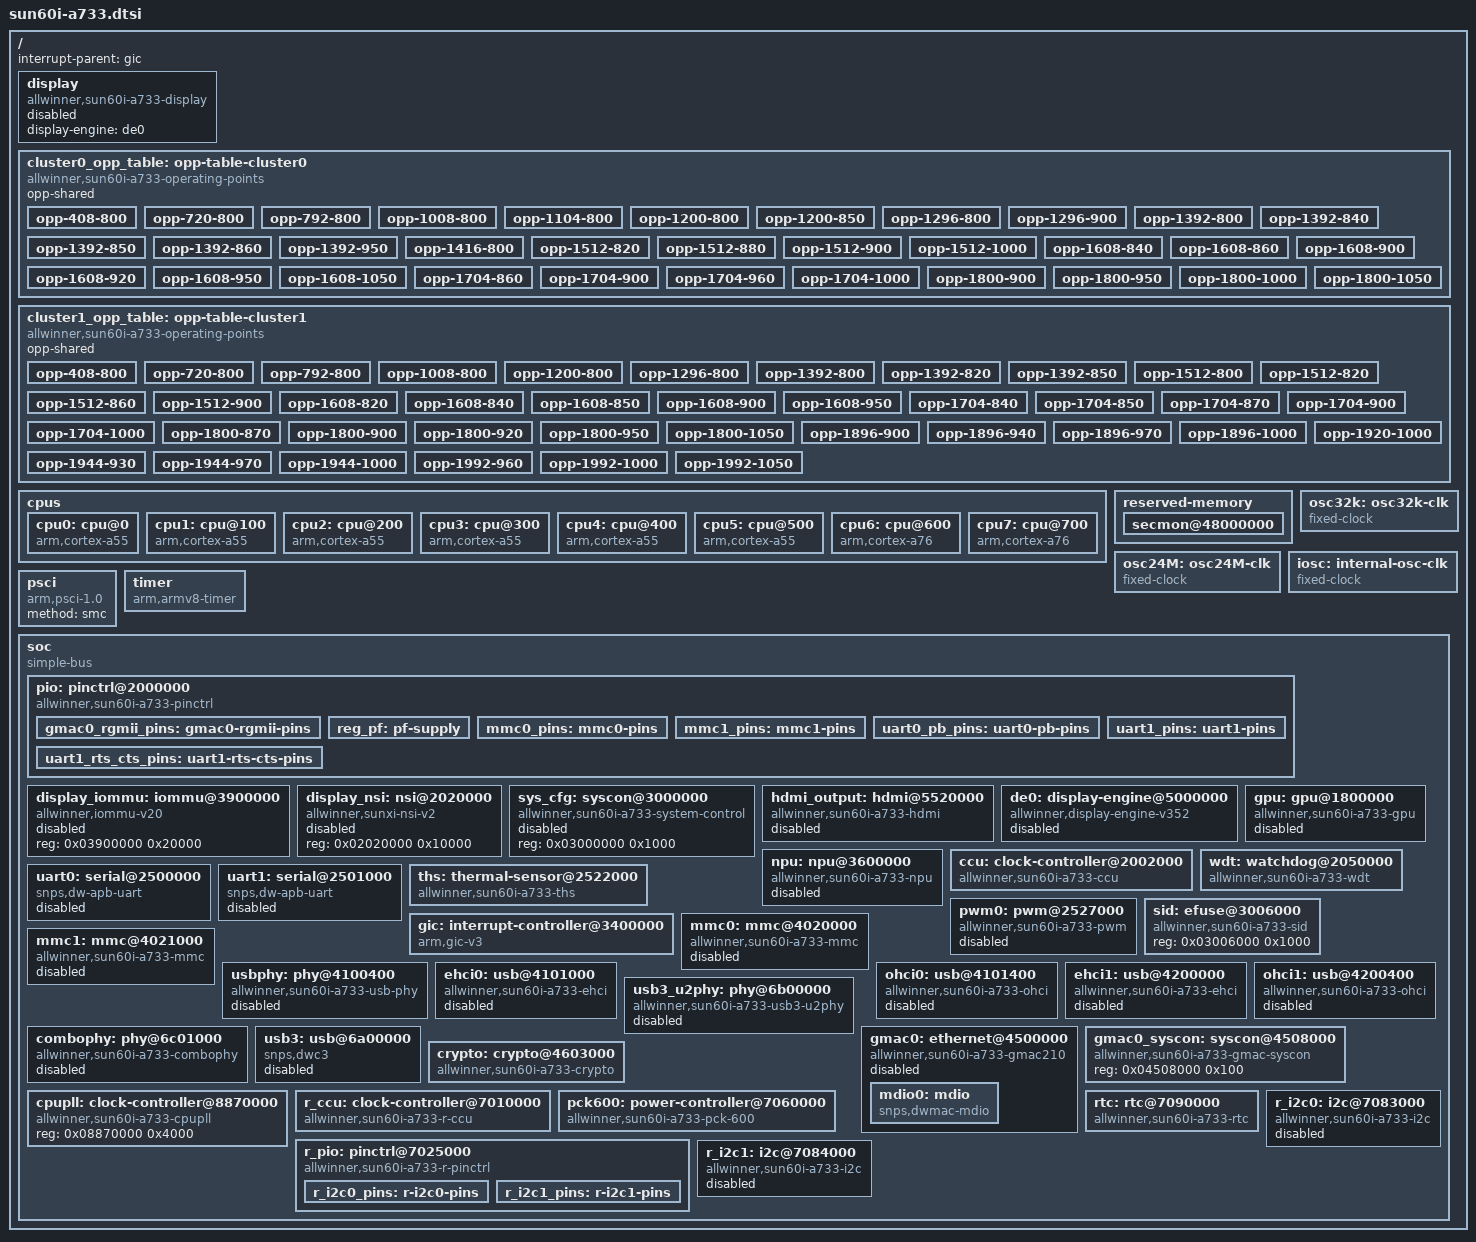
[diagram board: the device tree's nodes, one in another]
// SPDX-License-Identifier: (GPL-2.0-only OR MIT)
/*
 * Allwinner A733 (sun60iw2).
 *
 * Addresses and interrupt numbers were checked against the vendor kernel
 * tree and, where a register could be read, on an Orange Pi Zero 4.
 */

#include <dt-bindings/interrupt-controller/arm-gic.h>
#include <dt-bindings/clock/allwinner,sun60i-a733-ccu.h>
#include <dt-bindings/clock/allwinner,sun60i-a733-r-ccu.h>
#include <dt-bindings/reset/allwinner,sun60i-a733-ccu.h>
#include <dt-bindings/reset/allwinner,sun60i-a733-r-ccu.h>
#include <dt-bindings/power/allwinner,sun60i-a733-pck-600.h>

/ {
	/* This frontend does not enable DE, clocks or output at attach. */
	display: display {
		compatible = "allwinner,sun60i-a733-display";
		display-engine = <&de0>;
		status = "disabled";
	};

	interrupt-parent = <&gic>;
	#address-cells = <2>;
	#size-cells = <2>;

	/*
	 * Rates and supply voltages per speed grade. Bit n of
	 * "opp-supported-hw" stands for the n-th of the grades 0x00, 0x01,
	 * 0x02, 0x03, 0x04, 0x05, 0x06, 0x14 and 0x15 in the EFUSE. A board
	 * points its cores here together with their supplies: without a
	 * supply the higher rates must not be used.
	 */
	cluster0_opp_table: opp-table-cluster0 {
		compatible = "allwinner,sun60i-a733-operating-points";
		opp-shared;

		opp-408-800 {
			opp-hz = /bits/ 64 <408000000>;
			opp-microvolt = <800000>;
			opp-supported-hw = <0x1ff>;
			clock-latency-ns = <2000000>;
		};

		opp-720-800 {
			opp-hz = /bits/ 64 <720000000>;
			opp-microvolt = <800000>;
			opp-supported-hw = <0x001>;
			clock-latency-ns = <2000000>;
		};

		opp-792-800 {
			opp-hz = /bits/ 64 <792000000>;
			opp-microvolt = <800000>;
			opp-supported-hw = <0x1fe>;
			clock-latency-ns = <2000000>;
		};

		opp-1008-800 {
			opp-hz = /bits/ 64 <1008000000>;
			opp-microvolt = <800000>;
			opp-supported-hw = <0x1ff>;
			clock-latency-ns = <2000000>;
		};

		opp-1104-800 {
			opp-hz = /bits/ 64 <1104000000>;
			opp-microvolt = <800000>;
			opp-supported-hw = <0x002>;
			clock-latency-ns = <2000000>;
		};

		opp-1200-800 {
			opp-hz = /bits/ 64 <1200000000>;
			opp-microvolt = <800000>;
			opp-supported-hw = <0x1fd>;
			clock-latency-ns = <2000000>;
		};

		opp-1200-850 {
			opp-hz = /bits/ 64 <1200000000>;
			opp-microvolt = <850000>;
			opp-supported-hw = <0x002>;
			clock-latency-ns = <2000000>;
		};

		opp-1296-800 {
			opp-hz = /bits/ 64 <1296000000>;
			opp-microvolt = <800000>;
			opp-supported-hw = <0x004>;
			clock-latency-ns = <2000000>;
		};

		opp-1296-900 {
			opp-hz = /bits/ 64 <1296000000>;
			opp-microvolt = <900000>;
			opp-supported-hw = <0x002>;
			clock-latency-ns = <2000000>;
		};

		opp-1392-800 {
			opp-hz = /bits/ 64 <1392000000>;
			opp-microvolt = <800000>;
			opp-supported-hw = <0x1a0>;
			clock-latency-ns = <2000000>;
		};

		opp-1392-840 {
			opp-hz = /bits/ 64 <1392000000>;
			opp-microvolt = <840000>;
			opp-supported-hw = <0x050>;
			clock-latency-ns = <2000000>;
		};

		opp-1392-850 {
			opp-hz = /bits/ 64 <1392000000>;
			opp-microvolt = <850000>;
			opp-supported-hw = <0x004>;
			clock-latency-ns = <2000000>;
		};

		opp-1392-860 {
			opp-hz = /bits/ 64 <1392000000>;
			opp-microvolt = <860000>;
			opp-supported-hw = <0x008>;
			clock-latency-ns = <2000000>;
		};

		opp-1392-950 {
			opp-hz = /bits/ 64 <1392000000>;
			opp-microvolt = <950000>;
			opp-supported-hw = <0x002>;
			clock-latency-ns = <2000000>;
		};

		opp-1416-800 {
			opp-hz = /bits/ 64 <1416000000>;
			opp-microvolt = <800000>;
			opp-supported-hw = <0x001>;
			clock-latency-ns = <2000000>;
		};

		opp-1512-820 {
			opp-hz = /bits/ 64 <1512000000>;
			opp-microvolt = <820000>;
			opp-supported-hw = <0x1a0>;
			clock-latency-ns = <2000000>;
		};

		opp-1512-880 {
			opp-hz = /bits/ 64 <1512000000>;
			opp-microvolt = <880000>;
			opp-supported-hw = <0x010>;
			clock-latency-ns = <2000000>;
		};

		opp-1512-900 {
			opp-hz = /bits/ 64 <1512000000>;
			opp-microvolt = <900000>;
			opp-supported-hw = <0x004>;
			clock-latency-ns = <2000000>;
		};

		opp-1512-1000 {
			opp-hz = /bits/ 64 <1512000000>;
			opp-microvolt = <1000000>;
			opp-supported-hw = <0x002>;
			clock-latency-ns = <2000000>;
		};

		opp-1608-840 {
			opp-hz = /bits/ 64 <1608000000>;
			opp-microvolt = <840000>;
			opp-supported-hw = <0x100>;
			clock-latency-ns = <2000000>;
		};

		opp-1608-860 {
			opp-hz = /bits/ 64 <1608000000>;
			opp-microvolt = <860000>;
			opp-supported-hw = <0x0a0>;
			clock-latency-ns = <2000000>;
		};

		opp-1608-900 {
			opp-hz = /bits/ 64 <1608000000>;
			opp-microvolt = <900000>;
			opp-supported-hw = <0x001>;
			clock-latency-ns = <2000000>;
		};

		opp-1608-920 {
			opp-hz = /bits/ 64 <1608000000>;
			opp-microvolt = <920000>;
			opp-supported-hw = <0x010>;
			clock-latency-ns = <2000000>;
		};

		opp-1608-950 {
			opp-hz = /bits/ 64 <1608000000>;
			opp-microvolt = <950000>;
			opp-supported-hw = <0x004>;
			clock-latency-ns = <2000000>;
		};

		opp-1608-1050 {
			opp-hz = /bits/ 64 <1608000000>;
			opp-microvolt = <1050000>;
			opp-supported-hw = <0x002>;
			clock-latency-ns = <2000000>;
		};

		opp-1704-860 {
			opp-hz = /bits/ 64 <1704000000>;
			opp-microvolt = <860000>;
			opp-supported-hw = <0x100>;
			clock-latency-ns = <2000000>;
		};

		opp-1704-900 {
			opp-hz = /bits/ 64 <1704000000>;
			opp-microvolt = <900000>;
			opp-supported-hw = <0x0a0>;
			clock-latency-ns = <2000000>;
		};

		opp-1704-960 {
			opp-hz = /bits/ 64 <1704000000>;
			opp-microvolt = <960000>;
			opp-supported-hw = <0x010>;
			clock-latency-ns = <2000000>;
		};

		opp-1704-1000 {
			opp-hz = /bits/ 64 <1704000000>;
			opp-microvolt = <1000000>;
			opp-supported-hw = <0x004>;
			clock-latency-ns = <2000000>;
		};

		opp-1800-900 {
			opp-hz = /bits/ 64 <1800000000>;
			opp-microvolt = <900000>;
			opp-supported-hw = <0x100>;
			clock-latency-ns = <2000000>;
		};

		opp-1800-950 {
			opp-hz = /bits/ 64 <1800000000>;
			opp-microvolt = <950000>;
			opp-supported-hw = <0x0a0>;
			clock-latency-ns = <2000000>;
		};

		opp-1800-1000 {
			opp-hz = /bits/ 64 <1800000000>;
			opp-microvolt = <1000000>;
			opp-supported-hw = <0x011>;
			clock-latency-ns = <2000000>;
		};

		opp-1800-1050 {
			opp-hz = /bits/ 64 <1800000000>;
			opp-microvolt = <1050000>;
			opp-supported-hw = <0x004>;
			clock-latency-ns = <2000000>;
		};
	};

	cluster1_opp_table: opp-table-cluster1 {
		compatible = "allwinner,sun60i-a733-operating-points";
		opp-shared;

		opp-408-800 {
			opp-hz = /bits/ 64 <408000000>;
			opp-microvolt = <800000>;
			opp-supported-hw = <0x1ff>;
			clock-latency-ns = <2000000>;
		};

		opp-720-800 {
			opp-hz = /bits/ 64 <720000000>;
			opp-microvolt = <800000>;
			opp-supported-hw = <0x001>;
			clock-latency-ns = <2000000>;
		};

		opp-792-800 {
			opp-hz = /bits/ 64 <792000000>;
			opp-microvolt = <800000>;
			opp-supported-hw = <0x1fe>;
			clock-latency-ns = <2000000>;
		};

		opp-1008-800 {
			opp-hz = /bits/ 64 <1008000000>;
			opp-microvolt = <800000>;
			opp-supported-hw = <0x1ff>;
			clock-latency-ns = <2000000>;
		};

		opp-1200-800 {
			opp-hz = /bits/ 64 <1200000000>;
			opp-microvolt = <800000>;
			opp-supported-hw = <0x1ff>;
			clock-latency-ns = <2000000>;
		};

		opp-1296-800 {
			opp-hz = /bits/ 64 <1296000000>;
			opp-microvolt = <800000>;
			opp-supported-hw = <0x002>;
			clock-latency-ns = <2000000>;
		};

		opp-1392-800 {
			opp-hz = /bits/ 64 <1392000000>;
			opp-microvolt = <800000>;
			opp-supported-hw = <0x1f5>;
			clock-latency-ns = <2000000>;
		};

		opp-1392-820 {
			opp-hz = /bits/ 64 <1392000000>;
			opp-microvolt = <820000>;
			opp-supported-hw = <0x008>;
			clock-latency-ns = <2000000>;
		};

		opp-1392-850 {
			opp-hz = /bits/ 64 <1392000000>;
			opp-microvolt = <850000>;
			opp-supported-hw = <0x002>;
			clock-latency-ns = <2000000>;
		};

		opp-1512-800 {
			opp-hz = /bits/ 64 <1512000000>;
			opp-microvolt = <800000>;
			opp-supported-hw = <0x1e5>;
			clock-latency-ns = <2000000>;
		};

		opp-1512-820 {
			opp-hz = /bits/ 64 <1512000000>;
			opp-microvolt = <820000>;
			opp-supported-hw = <0x010>;
			clock-latency-ns = <2000000>;
		};

		opp-1512-860 {
			opp-hz = /bits/ 64 <1512000000>;
			opp-microvolt = <860000>;
			opp-supported-hw = <0x008>;
			clock-latency-ns = <2000000>;
		};

		opp-1512-900 {
			opp-hz = /bits/ 64 <1512000000>;
			opp-microvolt = <900000>;
			opp-supported-hw = <0x002>;
			clock-latency-ns = <2000000>;
		};

		opp-1608-820 {
			opp-hz = /bits/ 64 <1608000000>;
			opp-microvolt = <820000>;
			opp-supported-hw = <0x1a0>;
			clock-latency-ns = <2000000>;
		};

		opp-1608-840 {
			opp-hz = /bits/ 64 <1608000000>;
			opp-microvolt = <840000>;
			opp-supported-hw = <0x010>;
			clock-latency-ns = <2000000>;
		};

		opp-1608-850 {
			opp-hz = /bits/ 64 <1608000000>;
			opp-microvolt = <850000>;
			opp-supported-hw = <0x045>;
			clock-latency-ns = <2000000>;
		};

		opp-1608-900 {
			opp-hz = /bits/ 64 <1608000000>;
			opp-microvolt = <900000>;
			opp-supported-hw = <0x008>;
			clock-latency-ns = <2000000>;
		};

		opp-1608-950 {
			opp-hz = /bits/ 64 <1608000000>;
			opp-microvolt = <950000>;
			opp-supported-hw = <0x002>;
			clock-latency-ns = <2000000>;
		};

		opp-1704-840 {
			opp-hz = /bits/ 64 <1704000000>;
			opp-microvolt = <840000>;
			opp-supported-hw = <0x100>;
			clock-latency-ns = <2000000>;
		};

		opp-1704-850 {
			opp-hz = /bits/ 64 <1704000000>;
			opp-microvolt = <850000>;
			opp-supported-hw = <0x0a0>;
			clock-latency-ns = <2000000>;
		};

		opp-1704-870 {
			opp-hz = /bits/ 64 <1704000000>;
			opp-microvolt = <870000>;
			opp-supported-hw = <0x010>;
			clock-latency-ns = <2000000>;
		};

		opp-1704-900 {
			opp-hz = /bits/ 64 <1704000000>;
			opp-microvolt = <900000>;
			opp-supported-hw = <0x005>;
			clock-latency-ns = <2000000>;
		};

		opp-1704-1000 {
			opp-hz = /bits/ 64 <1704000000>;
			opp-microvolt = <1000000>;
			opp-supported-hw = <0x002>;
			clock-latency-ns = <2000000>;
		};

		opp-1800-870 {
			opp-hz = /bits/ 64 <1800000000>;
			opp-microvolt = <870000>;
			opp-supported-hw = <0x100>;
			clock-latency-ns = <2000000>;
		};

		opp-1800-900 {
			opp-hz = /bits/ 64 <1800000000>;
			opp-microvolt = <900000>;
			opp-supported-hw = <0x0a0>;
			clock-latency-ns = <2000000>;
		};

		opp-1800-920 {
			opp-hz = /bits/ 64 <1800000000>;
			opp-microvolt = <920000>;
			opp-supported-hw = <0x010>;
			clock-latency-ns = <2000000>;
		};

		opp-1800-950 {
			opp-hz = /bits/ 64 <1800000000>;
			opp-microvolt = <950000>;
			opp-supported-hw = <0x005>;
			clock-latency-ns = <2000000>;
		};

		opp-1800-1050 {
			opp-hz = /bits/ 64 <1800000000>;
			opp-microvolt = <1050000>;
			opp-supported-hw = <0x002>;
			clock-latency-ns = <2000000>;
		};

		opp-1896-900 {
			opp-hz = /bits/ 64 <1896000000>;
			opp-microvolt = <900000>;
			opp-supported-hw = <0x100>;
			clock-latency-ns = <2000000>;
		};

		opp-1896-940 {
			opp-hz = /bits/ 64 <1896000000>;
			opp-microvolt = <940000>;
			opp-supported-hw = <0x0a0>;
			clock-latency-ns = <2000000>;
		};

		opp-1896-970 {
			opp-hz = /bits/ 64 <1896000000>;
			opp-microvolt = <970000>;
			opp-supported-hw = <0x010>;
			clock-latency-ns = <2000000>;
		};

		opp-1896-1000 {
			opp-hz = /bits/ 64 <1896000000>;
			opp-microvolt = <1000000>;
			opp-supported-hw = <0x004>;
			clock-latency-ns = <2000000>;
		};

		opp-1920-1000 {
			opp-hz = /bits/ 64 <1920000000>;
			opp-microvolt = <1000000>;
			opp-supported-hw = <0x001>;
			clock-latency-ns = <2000000>;
		};

		opp-1944-930 {
			opp-hz = /bits/ 64 <1944000000>;
			opp-microvolt = <930000>;
			opp-supported-hw = <0x100>;
			clock-latency-ns = <2000000>;
		};

		opp-1944-970 {
			opp-hz = /bits/ 64 <1944000000>;
			opp-microvolt = <970000>;
			opp-supported-hw = <0x0a0>;
			clock-latency-ns = <2000000>;
		};

		opp-1944-1000 {
			opp-hz = /bits/ 64 <1944000000>;
			opp-microvolt = <1000000>;
			opp-supported-hw = <0x010>;
			clock-latency-ns = <2000000>;
		};

		opp-1992-960 {
			opp-hz = /bits/ 64 <1992000000>;
			opp-microvolt = <960000>;
			opp-supported-hw = <0x100>;
			clock-latency-ns = <2000000>;
		};

		opp-1992-1000 {
			opp-hz = /bits/ 64 <1992000000>;
			opp-microvolt = <1000000>;
			opp-supported-hw = <0x0a0>;
			clock-latency-ns = <2000000>;
		};

		opp-1992-1050 {
			opp-hz = /bits/ 64 <1992000000>;
			opp-microvolt = <1050000>;
			opp-supported-hw = <0x011>;
			clock-latency-ns = <2000000>;
		};
	};

	cpus {
		#address-cells = <1>;
		#size-cells = <0>;

		cpu0: cpu@0 {
			compatible = "arm,cortex-a55";
			device_type = "cpu";
			reg = <0x000>;
			enable-method = "psci";
			clocks = <&cpupll 0>;
		};

		cpu1: cpu@100 {
			compatible = "arm,cortex-a55";
			device_type = "cpu";
			reg = <0x100>;
			enable-method = "psci";
			clocks = <&cpupll 0>;
		};

		cpu2: cpu@200 {
			compatible = "arm,cortex-a55";
			device_type = "cpu";
			reg = <0x200>;
			enable-method = "psci";
			clocks = <&cpupll 0>;
		};

		cpu3: cpu@300 {
			compatible = "arm,cortex-a55";
			device_type = "cpu";
			reg = <0x300>;
			enable-method = "psci";
			clocks = <&cpupll 0>;
		};

		cpu4: cpu@400 {
			compatible = "arm,cortex-a55";
			device_type = "cpu";
			reg = <0x400>;
			enable-method = "psci";
			clocks = <&cpupll 0>;
		};

		cpu5: cpu@500 {
			compatible = "arm,cortex-a55";
			device_type = "cpu";
			reg = <0x500>;
			enable-method = "psci";
			clocks = <&cpupll 0>;
		};

		cpu6: cpu@600 {
			compatible = "arm,cortex-a76";
			device_type = "cpu";
			reg = <0x600>;
			enable-method = "psci";
			clocks = <&cpupll 1>;
		};

		cpu7: cpu@700 {
			compatible = "arm,cortex-a76";
			device_type = "cpu";
			reg = <0x700>;
			enable-method = "psci";
			clocks = <&cpupll 1>;
		};
	};

	reserved-memory {
		#address-cells = <2>;
		#size-cells = <2>;
		ranges;

		/* EL3 monitor (BL31) */
		secmon@48000000 {
			reg = <0x0 0x48000000 0x0 0x01000000>;
			no-map;
		};
	};

	osc24M: osc24M-clk {
		#clock-cells = <0>;
		compatible = "fixed-clock";
		clock-frequency = <24000000>;
		clock-output-names = "osc24M";
	};

	osc32k: osc32k-clk {
		#clock-cells = <0>;
		compatible = "fixed-clock";
		clock-frequency = <32768>;
		clock-output-names = "osc32k";
	};

	iosc: internal-osc-clk {
		#clock-cells = <0>;
		compatible = "fixed-clock";
		clock-frequency = <16000000>;
		clock-output-names = "iosc";
	};

	psci {
		compatible = "arm,psci-1.0";
		method = "smc";
	};

	timer {
		compatible = "arm,armv8-timer";
		interrupts = <GIC_PPI 13 IRQ_TYPE_LEVEL_LOW>,
			     <GIC_PPI 14 IRQ_TYPE_LEVEL_LOW>,
			     <GIC_PPI 11 IRQ_TYPE_LEVEL_LOW>,
			     <GIC_PPI 10 IRQ_TYPE_LEVEL_LOW>;
	};

	soc {
		compatible = "simple-bus";
		#address-cells = <1>;
		#size-cells = <1>;
		ranges = <0x0 0x0 0x0 0x40000000>;

		pio: pinctrl@2000000 {
			compatible = "allwinner,sun60i-a733-pinctrl";
			reg = <0x02000000 0x800>;
			clocks = <&ccu CLK_APB1>, <&osc24M>, <&osc32k>;
			clock-names = "apb", "hosc", "losc";
			gpio-controller;
			#gpio-cells = <3>;

			gmac0_rgmii_pins: gmac0-rgmii-pins {
				pins = "PH0", "PH1", "PH2", "PH3",
				       "PH4", "PH5", "PH6", "PH7",
				       "PH8", "PH9", "PH10", "PH11",
				       "PH12", "PH13", "PH14", "PH15";
				function = "gmac0";
				allwinner,pinmux = <5>;
				drive-strength = <20>;
				bias-pull-up;
			};

			/* The chip switches the supply of bank PF itself. */
			reg_pf: pf-supply {
				regulator-name = "vcc-pf";
				regulator-min-microvolt = <1800000>;
				regulator-max-microvolt = <3300000>;
			};

			mmc0_pins: mmc0-pins {
				pins = "PF0", "PF1", "PF2", "PF3", "PF4", "PF5";
				function = "mmc0";
				allwinner,pinmux = <2>;
				drive-strength = <30>;
				bias-pull-up;
			};

			mmc1_pins: mmc1-pins {
				pins = "PG0", "PG1", "PG2", "PG3", "PG4", "PG5";
				function = "mmc1";
				allwinner,pinmux = <2>;
				drive-strength = <20>;
				bias-pull-up;
			};

			uart0_pb_pins: uart0-pb-pins {
				pins = "PB9", "PB10";
				function = "uart0";
				allwinner,pinmux = <2>;
			};

			uart1_pins: uart1-pins {
				pins = "PG6", "PG7";
				function = "uart1";
				allwinner,pinmux = <2>;
			};

			uart1_rts_cts_pins: uart1-rts-cts-pins {
				pins = "PG8", "PG9";
				function = "uart1";
				allwinner,pinmux = <2>;
			};
		};

		/* Origin: EmberBSD, AI-assisted; native DE memory resource facts.
		 * These nodes do not register active IOMMU or NSI providers. */
		display_iommu: iommu@3900000 {
			compatible = "allwinner,iommu-v20";
			reg = <0x03900000 0x20000>;
			#iommu-cells = <2>;
			status = "disabled";
		};

		display_nsi: nsi@2020000 {
			compatible = "allwinner,sunxi-nsi-v2";
			reg = <0x02020000 0x10000>;
			#nsi-cells = <1>;
			status = "disabled";
		};

		/* Shared SYS_CFG access uses the native syscon mutex. */
		sys_cfg: syscon@3000000 {
			compatible = "allwinner,sun60i-a733-system-control", "syscon";
			reg = <0x03000000 0x1000>;
			status = "disabled";
		};

		/* Register the native provider. The DE coordinator starts output. */
		hdmi_output: hdmi@5520000 {
			compatible = "allwinner,sun60i-a733-hdmi";
			reg = <0x05520000 0x100000>, <0x05510000 0x1000>,
			      <0x05730000 0x1000>;
			reg-names = "hdmi", "vo1", "tv0";
			clocks = <&ccu CLK_DE0>;
			clock-names = "de0";
			power-domains = <&pck600 PD_VO1>;
			netbsd,consumer-managed-power;
			netbsd,dcxo-source = <&rtc>;
			syscon = <&sys_cfg>;
			status = "disabled";
		};

		/* An enabled board must supply its native output provider. */
		de0: display-engine@5000000 {
			compatible = "allwinner,display-engine-v352";
			reg = <0x05000000 0x400000>;
			clocks = <&ccu CLK_DE0>;
			clock-names = "de0";
			power-domains = <&pck600 PD_DE_SYS>;
			iommus = <&display_iommu 8 1>;
			nsi = <&display_nsi 2>;
			netbsd,consumer-managed-power;
			status = "disabled";
		};

		/* Origin: EmberBSD; GPU identity only, no automatic power-on. */
		gpu: gpu@1800000 {
			compatible = "allwinner,sun60i-a733-gpu",
				     "img,img-bxm-4-64", "img,img-rogue";
			reg = <0x01800000 0x8ffff>;
			interrupts = <GIC_SPI 63 IRQ_TYPE_LEVEL_HIGH>;
			clocks = <&ccu CLK_GPU0>;
			clock-names = "core";
			resets = <&ccu RST_BUS_GPU0>;
			power-domains = <&pck600 PD_GPU_TOP>;
			netbsd,consumer-managed-power;
			/* Local diagnostic stage: never map or read GPU registers. */
			netbsd,observe-only;
			status = "disabled";
		};

		/* Origin: EmberBSD; NPU identity only, no automatic power-on. */
		npu: npu@3600000 {
			compatible = "allwinner,sun60i-a733-npu";
			reg = <0x03600000 0x1000>;
			interrupts = <GIC_SPI 65 IRQ_TYPE_LEVEL_HIGH>;
			clocks = <&ccu CLK_NPU>, <&ccu CLK_PLL_NPU>,
				 <&ccu CLK_BUS_NPU>, <&ccu CLK_MBUS_NPU>,
				 <&ccu CLK_AHB_NPU>;
			clock-names = "clk_npu", "clk_parent", "clk_bus",
				"clk_mbus_gate", "clk_ahb_gate";
			resets = <&ccu RST_BUS_NPU_AHB>,
				 <&ccu RST_BUS_NPU_AXI>,
				 <&ccu RST_BUS_NPU_CORE>;
			reset-names = "npu_ahb_rst", "npu_axi_rst", "npu_rst";
			power-domains = <&pck600 4>;
			netbsd,consumer-managed-power;
			netbsd,observe-only;
			status = "disabled";
		};

		ccu: clock-controller@2002000 {
			compatible = "allwinner,sun60i-a733-ccu";
			/* Local read-only hardware oscillator observation source. */
			netbsd,dcxo-source = <&rtc>;
			reg = <0x02002000 0x2000>;
			clocks = <&osc24M>, <&osc32k>, <&iosc>, <&osc32k>;
			clock-names = "hosc", "losc", "iosc", "losc-fanout";
			#clock-cells = <1>;
			#reset-cells = <1>;
		};

		/* The same register layout as on the A523. */
		wdt: watchdog@2050000 {
			compatible = "allwinner,sun60i-a733-wdt",
				     "allwinner,sun55i-a523-wdt";
			reg = <0x02050000 0x20>;
			interrupts = <GIC_SPI 106 IRQ_TYPE_LEVEL_HIGH>;
			clocks = <&osc24M>, <&osc32k>;
			clock-names = "hosc", "losc";
		};

		uart0: serial@2500000 {
			compatible = "snps,dw-apb-uart";
			reg = <0x02500000 0x400>;
			interrupts = <GIC_SPI 2 IRQ_TYPE_LEVEL_HIGH>;
			reg-shift = <2>;
			reg-io-width = <4>;
			fifo-size = <64>;
			clocks = <&ccu CLK_BUS_UART0>;
			resets = <&ccu RST_BUS_UART0>;
			status = "disabled";
		};

		uart1: serial@2501000 {
			compatible = "snps,dw-apb-uart";
			reg = <0x02501000 0x400>;
			interrupts = <GIC_SPI 3 IRQ_TYPE_LEVEL_HIGH>;
			reg-shift = <2>;
			reg-io-width = <4>;
			fifo-size = <256>;
			clocks = <&ccu CLK_BUS_UART1>;
			resets = <&ccu RST_BUS_UART1>;
			status = "disabled";
		};

		/* Not an upstream binding yet. */
		ths: thermal-sensor@2522000 {
			compatible = "allwinner,sun60i-a733-ths";
			reg = <0x02522000 0x400>;
			clocks = <&ccu CLK_BUS_THS0>, <&ccu CLK_GPADC0_24M>;
			clock-names = "bus", "gpadc";
			resets = <&ccu RST_BUS_THS0>;
			#thermal-sensor-cells = <1>;
		};

		/* Native continuous PWM binding; capture is not implemented. */
		pwm0: pwm@2527000 {
			compatible = "allwinner,sun60i-a733-pwm";
			reg = <0x02527000 0x400>;
			clocks = <&ccu CLK_BUS_PWM0>, <&ccu CLK_BUS_PWM0>;
			clock-names = "bus", "hosc";
			resets = <&ccu RST_BUS_PWM0>;
			#pwm-cells = <3>;
			status = "disabled";
		};

		/* Not an upstream binding yet. */
		sid: efuse@3006000 {
			compatible = "allwinner,sun60i-a733-sid";
			reg = <0x03006000 0x1000>;
		};

		gic: interrupt-controller@3400000 {
			compatible = "arm,gic-v3";
			reg = <0x03400000 0x10000>,
			      <0x03460000 0x100000>;
			interrupts = <GIC_PPI 9 IRQ_TYPE_LEVEL_HIGH>;
			interrupt-controller;
			#interrupt-cells = <3>;
		};

		mmc0: mmc@4020000 {
			compatible = "allwinner,sun60i-a733-mmc",
				     "allwinner,sun20i-d1-mmc";
			reg = <0x04020000 0x1000>;
			interrupts = <GIC_SPI 161 IRQ_TYPE_LEVEL_HIGH>;
			clocks = <&ccu CLK_BUS_MMC0>, <&ccu CLK_MMC0>;
			clock-names = "ahb", "mmc";
			resets = <&ccu RST_BUS_MMC0>;
			reset-names = "ahb";
			max-frequency = <150000000>;
			cap-sd-highspeed;
			#address-cells = <1>;
			#size-cells = <0>;
			status = "disabled";
		};

		mmc1: mmc@4021000 {
			compatible = "allwinner,sun60i-a733-mmc",
				     "allwinner,sun20i-d1-mmc";
			reg = <0x04021000 0x1000>;
			interrupts = <GIC_SPI 162 IRQ_TYPE_LEVEL_HIGH>;
			clocks = <&ccu CLK_BUS_MMC1>, <&ccu CLK_MMC1>;
			clock-names = "ahb", "mmc";
			resets = <&ccu RST_BUS_MMC1>;
			reset-names = "ahb";
			max-frequency = <150000000>;
			cap-sd-highspeed;
			cap-sdio-irq;
			#address-cells = <1>;
			#size-cells = <0>;
			status = "disabled";
		};

		usbphy: phy@4100400 {
			compatible = "allwinner,sun60i-a733-usb-phy";
			reg = <0x04100400 0x100>,
			      <0x04101800 0x100>,
			      <0x04200800 0x100>;
			reg-names = "phy_ctrl", "pmu0", "pmu1";
			clocks = <&ccu CLK_USB_OHCI0>, <&ccu CLK_USB_OHCI1>;
			clock-names = "usb0_phy", "usb1_phy";
			resets = <&ccu RST_USB_PHY0>, <&ccu RST_USB_PHY1>;
			reset-names = "usb0_reset", "usb1_reset";
			#phy-cells = <1>;
			status = "disabled";
		};

		ehci0: usb@4101000 {
			compatible = "allwinner,sun60i-a733-ehci", "generic-ehci";
			reg = <0x04101000 0x100>;
			interrupts = <GIC_SPI 157 IRQ_TYPE_LEVEL_HIGH>;
			clocks = <&ccu CLK_BUS_OHCI0>, <&ccu CLK_BUS_EHCI0>,
				 <&ccu CLK_USB_OHCI0>;
			resets = <&ccu RST_BUS_OHCI0>, <&ccu RST_BUS_EHCI0>;
			phys = <&usbphy 0>;
			phy-names = "usb";
			status = "disabled";
		};

		ohci0: usb@4101400 {
			compatible = "allwinner,sun60i-a733-ohci", "generic-ohci";
			reg = <0x04101400 0x100>;
			interrupts = <GIC_SPI 158 IRQ_TYPE_LEVEL_HIGH>;
			clocks = <&ccu CLK_BUS_OHCI0>, <&ccu CLK_USB_OHCI0>;
			resets = <&ccu RST_BUS_OHCI0>;
			phys = <&usbphy 0>;
			phy-names = "usb";
			status = "disabled";
		};

		ehci1: usb@4200000 {
			compatible = "allwinner,sun60i-a733-ehci", "generic-ehci";
			reg = <0x04200000 0x100>;
			interrupts = <GIC_SPI 159 IRQ_TYPE_LEVEL_HIGH>;
			clocks = <&ccu CLK_BUS_OHCI1>, <&ccu CLK_BUS_EHCI1>,
				 <&ccu CLK_USB_OHCI1>;
			resets = <&ccu RST_BUS_OHCI1>, <&ccu RST_BUS_EHCI1>;
			phys = <&usbphy 1>;
			phy-names = "usb";
			status = "disabled";
		};

		ohci1: usb@4200400 {
			compatible = "allwinner,sun60i-a733-ohci", "generic-ohci";
			reg = <0x04200400 0x100>;
			interrupts = <GIC_SPI 160 IRQ_TYPE_LEVEL_HIGH>;
			clocks = <&ccu CLK_BUS_OHCI1>, <&ccu CLK_USB_OHCI1>;
			resets = <&ccu RST_BUS_OHCI1>;
			phys = <&usbphy 1>;
			phy-names = "usb";
			status = "disabled";
		};

		/*
		 * The USB 3 port. Its controller and PHYs belong to the
		 * high speed subsystem at 0x06c00000, whose bus gates the
		 * USB 2.0 PHY driver opens; that is the PHY's second
		 * register range. The compatible string of the PHY is not
		 * an upstream binding. The serdes for SuperSpeed is not
		 * described, so the port runs at USB 2.0 rates.
		 */
		usb3_u2phy: phy@6b00000 {
			compatible = "allwinner,sun60i-a733-usb3-u2phy";
			reg = <0x06b00000 0x800>, <0x06c00000 0x400>;
			clocks = <&ccu CLK_USB2_U2_REF>,
				 <&ccu CLK_USB2_U2_PIPE>;
			assigned-clocks = <&ccu CLK_USB2_U2_PIPE>;
			assigned-clock-parents = <&ccu CLK_PLL_PERIPH0_480M>;
			assigned-clock-rates = <120000000>;
			allwinner,phy-tune = <0x143338d6>;
			#phy-cells = <0>;
			status = "disabled";
		};

		/*
		 * The serdes behind the SuperSpeed lanes of the Type-C
		 * port. Registers: the PHY's pins, the PHY itself, the
		 * lane routing, the subsystem's gates, and the gate of
		 * the oscillator's outputs in the real-time clock. The
		 * compatible string is not an upstream binding.
		 */
		combophy: phy@6c01000 {
			compatible = "allwinner,sun60i-a733-combophy";
			reg = <0x06c01000 0xa00>, <0x06c80000 0x20000>,
			      <0x06c06000 0x2000>, <0x06c00000 0x400>,
			      <0x0709016c 0x4>;
			clocks = <&ccu CLK_SERDES_PHY>;
			assigned-clocks = <&ccu CLK_SERDES_PHY>;
			assigned-clock-parents = <&ccu CLK_PLL_PERIPH0_600M>;
			assigned-clock-rates = <100000000>;
			resets = <&ccu RST_BUS_SERDES>;
			#phy-cells = <0>;
			status = "disabled";
		};

		usb3: usb@6a00000 {
			compatible = "snps,dwc3";
			reg = <0x06a00000 0x100000>;
			interrupts = <GIC_SPI 155 IRQ_TYPE_LEVEL_HIGH>;
			clocks = <&ccu CLK_USB2_MF>, <&ccu CLK_USB2_U2_REF>,
				 <&ccu CLK_USB2_SUSPEND>;
			clock-names = "bus_clk", "ref_clk", "suspend";
			/*
			 * The controller counts its frames from the
			 * bus clock and expects 24 MHz there.
			 */
			assigned-clocks = <&ccu CLK_USB2_SUSPEND>,
					  <&ccu CLK_USB2_MF>;
			assigned-clock-parents = <&ccu CLK_SYS_24M>,
						 <&ccu CLK_SYS_24M>;
			resets = <&ccu RST_BUS_USB2>;
			dr_mode = "host";
			phy_type = "utmi";
			snps,dis_enblslpm_quirk;
			snps,dis_u3_susphy_quirk;
			snps,dis_u2_susphy_quirk;
			phys = <&usb3_u2phy>, <&combophy>;
			phy-names = "usb2-phy", "usb3-phy";
			status = "disabled";
		};

		/*
		 * The compatible string is not an upstream binding yet;
		 * the Linux driver for the A523 calls its controller
		 * allwinner,sun55i-a523-gmac200.
		 */
		gmac0: ethernet@4500000 {
			compatible = "allwinner,sun60i-a733-gmac210";
			reg = <0x04500000 0x8000>;
			interrupts = <GIC_SPI 172 IRQ_TYPE_LEVEL_HIGH>;
			interrupt-names = "macirq";
			clocks = <&ccu CLK_BUS_GMAC0>, <&ccu CLK_MBUS_GMAC0>,
				 <&ccu CLK_GMAC0_PHY>;
			clock-names = "stmmaceth", "mbus", "phy";
			assigned-clocks = <&ccu CLK_GMAC0_PHY>;
			assigned-clock-rates = <25000000>;
			resets = <&ccu RST_BUS_GMAC0>, <&ccu RST_BUS_GMAC0_AXI>;
			reset-names = "stmmaceth", "ahb";
			syscon = <&gmac0_syscon>;
			status = "disabled";

			mdio0: mdio {
				compatible = "snps,dwmac-mdio";
				#address-cells = <1>;
				#size-cells = <0>;
			};
		};

		gmac0_syscon: syscon@4508000 {
			compatible = "allwinner,sun60i-a733-gmac-syscon",
				     "syscon";
			reg = <0x04508000 0x100>;
		};

		/* Not an upstream binding yet. */
		crypto: crypto@4603000 {
			compatible = "allwinner,sun60i-a733-crypto";
			reg = <0x04603000 0x800>;
			interrupts = <GIC_SPI 168 IRQ_TYPE_EDGE_RISING>;
			clocks = <&ccu CLK_BUS_CE>, <&ccu CLK_CE>,
				 <&ccu CLK_MBUS_CE>, <&ccu CLK_BUS_CE_SYS>;
			clock-names = "bus", "mod", "ram", "sys";
			resets = <&ccu RST_BUS_CE>;
		};

		/* Not an upstream binding yet. Clock 0: little cores, 1: big. */
		cpupll: clock-controller@8870000 {
			compatible = "allwinner,sun60i-a733-cpupll";
			reg = <0x08870000 0x4000>;
			#clock-cells = <1>;
		};

		r_ccu: clock-controller@7010000 {
			compatible = "allwinner,sun60i-a733-r-ccu";
			reg = <0x07010000 0x400>;
			clocks = <&osc24M>, <&osc32k>, <&iosc>;
			clock-names = "hosc", "losc", "iosc";
			#clock-cells = <1>;
			#reset-cells = <1>;
		};

		/* No consumer is powered merely by attaching this provider. */
		pck600: power-controller@7060000 {
			compatible = "allwinner,sun60i-a733-pck-600";
			reg = <0x07060000 0xb000>;
			clocks = <&r_ccu CLK_BUS_R_PPU>;
			#power-domain-cells = <1>;
		};

		/* Pins of the always-on domain. */
		r_pio: pinctrl@7025000 {
			compatible = "allwinner,sun60i-a733-r-pinctrl";
			reg = <0x07025000 0x400>;
			gpio-controller;
			#gpio-cells = <3>;

			r_i2c0_pins: r-i2c0-pins {
				pins = "PL0", "PL1";
				function = "s_twi0";
				allwinner,pinmux = <2>;
				bias-pull-up;
			};

			r_i2c1_pins: r-i2c1-pins {
				pins = "PL12", "PL13";
				function = "s_twi1";
				allwinner,pinmux = <3>;
				bias-pull-up;
			};
		};

		rtc: rtc@7090000 {
			compatible = "allwinner,sun60i-a733-rtc";
			reg = <0x07090000 0x400>;
			interrupts = <GIC_SPI 196 IRQ_TYPE_LEVEL_HIGH>;
		};

		r_i2c0: i2c@7083000 {
			compatible = "allwinner,sun60i-a733-i2c",
				     "allwinner,sun6i-a31-i2c";
			reg = <0x07083000 0x400>;
			interrupts = <GIC_SPI 203 IRQ_TYPE_LEVEL_HIGH>;
			clocks = <&r_ccu CLK_BUS_R_I2C0>;
			resets = <&r_ccu RST_BUS_R_I2C0>;
			pinctrl-names = "default";
			pinctrl-0 = <&r_i2c0_pins>;
			#address-cells = <1>;
			#size-cells = <0>;
			status = "disabled";
		};

		r_i2c1: i2c@7084000 {
			compatible = "allwinner,sun60i-a733-i2c",
				     "allwinner,sun6i-a31-i2c";
			reg = <0x07084000 0x400>;
			interrupts = <GIC_SPI 204 IRQ_TYPE_LEVEL_HIGH>;
			clocks = <&r_ccu CLK_BUS_R_I2C1>;
			resets = <&r_ccu RST_BUS_R_I2C1>;
			pinctrl-names = "default";
			pinctrl-0 = <&r_i2c1_pins>;
			#address-cells = <1>;
			#size-cells = <0>;
			status = "disabled";
		};
	};
};
